# iostr731 register map
Registers are 16-bit, access not given, no defined reset value unless marked. A register's access mark holds for its fields unless they carry their own. Addresses are absolute; registers are grouped by the start of their names; [hi:lo] are bit positions; {n}, {i} and the like mark numbered series.

## I2C1
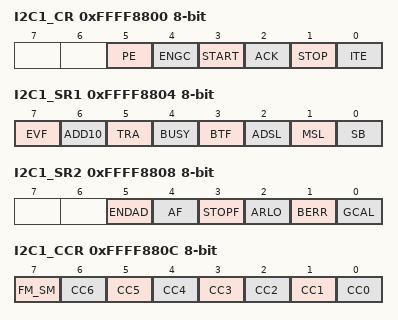
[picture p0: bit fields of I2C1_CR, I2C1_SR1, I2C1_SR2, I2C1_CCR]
0xFFFF8800 I2C1_CR 8-bit
  [5] PE, [4] ENGC, [3] START, [2] ACK, [1] STOP, [0] ITE
0xFFFF8804 I2C1_SR1 8-bit
  [7] EVF, [6] ADD10, [5] TRA, [4] BUSY, [3] BTF, [2] ADSL, [1] MSL, [0] SB
0xFFFF8808 I2C1_SR2 8-bit
  [5] ENDAD, [4] AF, [3] STOPF, [2] ARLO, [1] BERR, [0] GCAL
0xFFFF880C I2C1_CCR 8-bit
  [7] FM_SM, [n] CC{n} (n=0..6)
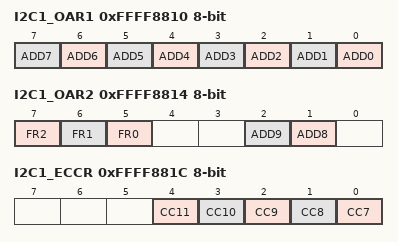
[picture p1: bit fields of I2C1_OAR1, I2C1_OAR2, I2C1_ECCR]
0xFFFF8810 I2C1_OAR1 8-bit
  [n] ADD{n} (n=0..7)
0xFFFF8814 I2C1_OAR2 8-bit
  [7] FR2, [6] FR1, [5] FR0, [2] ADD9, [1] ADD8
0xFFFF8818 I2C1_DR 8-bit
0xFFFF881C I2C1_ECCR 8-bit
  [n-7] CC{n} (n=7..11)

## TB0
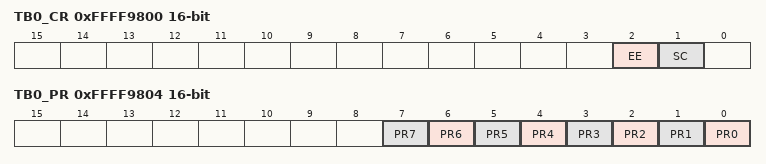
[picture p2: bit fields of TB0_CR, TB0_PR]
0xFFFF9800 TB0_CR
  [2] EE, [1] SC
0xFFFF9804 TB0_PR
  [n] PR{n} (n=0..7)
0xFFFF9808 TB0_VR
0xFFFF980C TB0_CNT
0xFFFF9810 TB0_SR
  [0] EC
0xFFFF9814 TB0_MR
  [0] ECM

## TB1
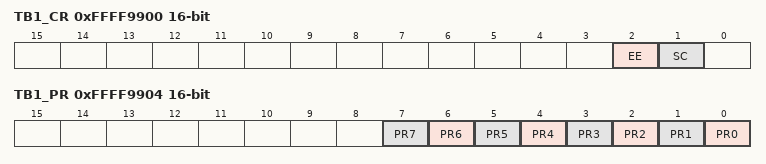
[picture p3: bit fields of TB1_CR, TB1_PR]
0xFFFF9900 TB1_CR
  [2] EE, [1] SC
0xFFFF9904 TB1_PR
  [n] PR{n} (n=0..7)
0xFFFF9908 TB1_VR
0xFFFF990C TB1_CNT
0xFFFF9910 TB1_SR
  [0] EC
0xFFFF9914 TB1_MR
  [0] ECM

## TB2
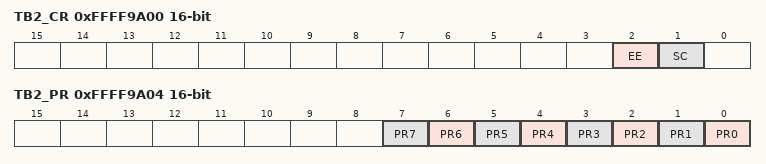
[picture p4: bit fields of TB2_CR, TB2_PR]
0xFFFF9A00 TB2_CR
  [2] EE, [1] SC
0xFFFF9A04 TB2_PR
  [n] PR{n} (n=0..7)
0xFFFF9A08 TB2_VR
0xFFFF9A0C TB2_CNT
0xFFFF9A10 TB2_SR
  [0] EC
0xFFFF9A14 TB2_MR
  [0] ECM

## UART0
0xFFFF9C00 UART0_BR
0xFFFF9C04 UART0_TXBUFR
  [8:0] TX
0xFFFF9C08 UART0_RXBUFR
  [9:0] RX
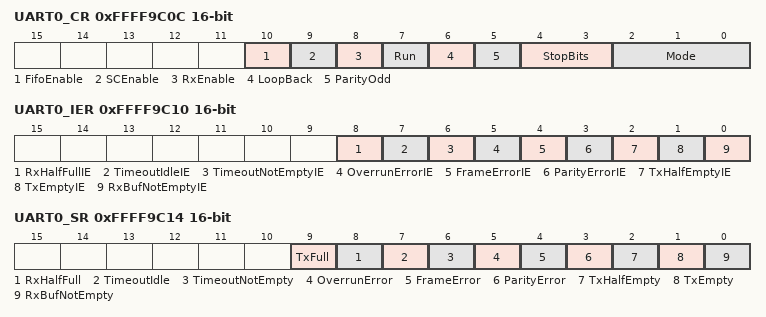
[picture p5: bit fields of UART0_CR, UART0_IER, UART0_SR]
0xFFFF9C0C UART0_CR
  [10] FifoEnable, [9] SCEnable, [8] RxEnable, [7] Run, [6] LoopBack, [5] ParityOdd, [4:3] StopBits, [2:0] Mode
0xFFFF9C10 UART0_IER
  [8] RxHalfFullIE, [7] TimeoutIdleIE, [6] TimeoutNotEmptyIE, [5] OverrunErrorIE, [4] FrameErrorIE, [3] ParityErrorIE, [2] TxHalfEmptyIE, [1] TxEmptyIE, [0] RxBufNotEmptyIE
0xFFFF9C14 UART0_SR
  [9] TxFull, [8] RxHalfFull, [7] TimeoutIdle, [6] TimeoutNotEmpty, [5] OverrunError, [4] FrameError, [3] ParityError, [2] TxHalfEmpty, [1] TxEmpty, [0] RxBufNotEmpty
0xFFFF9C1C UART0_TOR
  [7:0] Timeout
0xFFFF9C20 UART0_TXRSTR
0xFFFF9C24 UART0_RXRSTR

## UART2
0xFFFF9E00 UART2_BR
0xFFFF9E04 UART2_TXBUFR
  [8:0] TX
0xFFFF9E08 UART2_RXBUFR
  [9:0] RX
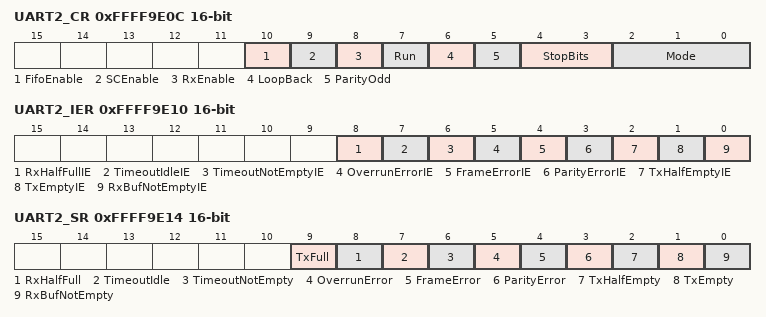
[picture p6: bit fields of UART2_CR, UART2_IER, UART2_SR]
0xFFFF9E0C UART2_CR
  [10] FifoEnable, [9] SCEnable, [8] RxEnable, [7] Run, [6] LoopBack, [5] ParityOdd, [4:3] StopBits, [2:0] Mode
0xFFFF9E10 UART2_IER
  [8] RxHalfFullIE, [7] TimeoutIdleIE, [6] TimeoutNotEmptyIE, [5] OverrunErrorIE, [4] FrameErrorIE, [3] ParityErrorIE, [2] TxHalfEmptyIE, [1] TxEmptyIE, [0] RxBufNotEmptyIE
0xFFFF9E14 UART2_SR
  [9] TxFull, [8] RxHalfFull, [7] TimeoutIdle, [6] TimeoutNotEmpty, [5] OverrunError, [4] FrameError, [3] ParityError, [2] TxHalfEmpty, [1] TxEmpty, [0] RxBufNotEmpty
0xFFFF9E1C UART2_TOR
  [7:0] Timeout
0xFFFF9E20 UART2_TXRSTR
0xFFFF9E24 UART2_RXRSTR

## UART1
0xFFFFA000 UART1_BR
0xFFFFA004 UART1_TXBUFR
  [8:0] TX
0xFFFFA008 UART1_RXBUFR
  [9:0] RX
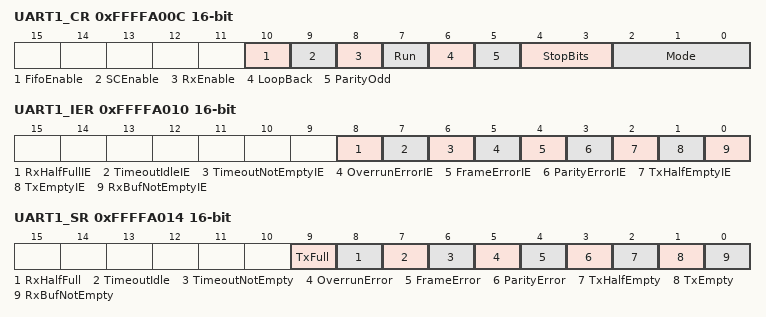
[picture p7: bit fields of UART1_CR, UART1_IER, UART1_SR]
0xFFFFA00C UART1_CR
  [10] FifoEnable, [9] SCEnable, [8] RxEnable, [7] Run, [6] LoopBack, [5] ParityOdd, [4:3] StopBits, [2:0] Mode
0xFFFFA010 UART1_IER
  [8] RxHalfFullIE, [7] TimeoutIdleIE, [6] TimeoutNotEmptyIE, [5] OverrunErrorIE, [4] FrameErrorIE, [3] ParityErrorIE, [2] TxHalfEmptyIE, [1] TxEmptyIE, [0] RxBufNotEmptyIE
0xFFFFA014 UART1_SR
  [9] TxFull, [8] RxHalfFull, [7] TimeoutIdle, [6] TimeoutNotEmpty, [5] OverrunError, [4] FrameError, [3] ParityError, [2] TxHalfEmpty, [1] TxEmpty, [0] RxBufNotEmpty
0xFFFFA01C UART1_TOR
  [7:0] Timeout
0xFFFFA020 UART1_TXRSTR
0xFFFFA024 UART1_RXRSTR

## UART3
0xFFFFA200 UART3_BR
0xFFFFA204 UART3_TXBUFR
  [8:0] TX
0xFFFFA208 UART3_RXBUFR
  [9:0] RX
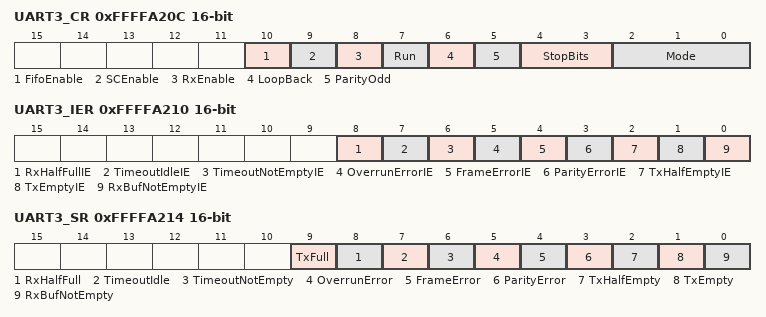
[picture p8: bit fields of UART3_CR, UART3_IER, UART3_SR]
0xFFFFA20C UART3_CR
  [10] FifoEnable, [9] SCEnable, [8] RxEnable, [7] Run, [6] LoopBack, [5] ParityOdd, [4:3] StopBits, [2:0] Mode
0xFFFFA210 UART3_IER
  [8] RxHalfFullIE, [7] TimeoutIdleIE, [6] TimeoutNotEmptyIE, [5] OverrunErrorIE, [4] FrameErrorIE, [3] ParityErrorIE, [2] TxHalfEmptyIE, [1] TxEmptyIE, [0] RxBufNotEmptyIE
0xFFFFA214 UART3_SR
  [9] TxFull, [8] RxHalfFull, [7] TimeoutIdle, [6] TimeoutNotEmpty, [5] OverrunError, [4] FrameError, [3] ParityError, [2] TxHalfEmpty, [1] TxEmpty, [0] RxBufNotEmpty
0xFFFFA21C UART3_TOR
  [7:0] Timeout
0xFFFFA220 UART3_TXRSTR
0xFFFFA224 UART3_RXRSTR
